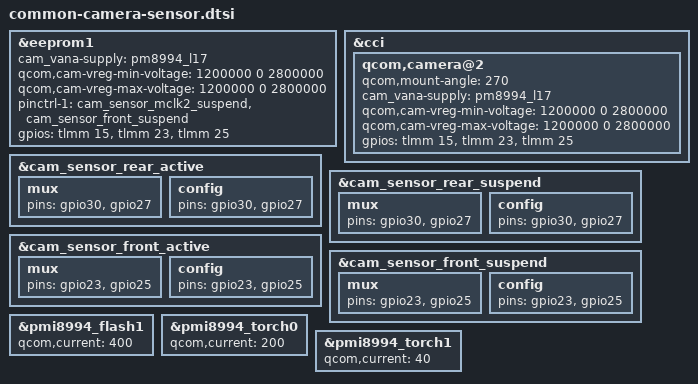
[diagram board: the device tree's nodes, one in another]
&eeprom1 {
	cam_vana-supply = <&pm8994_l17>;
	qcom,cam-vreg-min-voltage = <1200000 0 2800000>;
	qcom,cam-vreg-max-voltage = <1200000 0 2800000>;
	pinctrl-1 = <&cam_sensor_mclk2_suspend &cam_sensor_front_suspend>;
	gpios = <&tlmm 15 0>,
			<&tlmm 23 0>,
			<&tlmm 25 0>;
	/delete-property/ qcom,clock-rates;
};

&cci {
	/delete-node/ qcom,camera@1;
	
	qcom,camera@2 {
		qcom,mount-angle = <270>;
		/delete-property/ qcom,actuator-src;
		cam_vana-supply = <&pm8994_l17>;
		qcom,cam-vreg-min-voltage = <1200000 0 2800000>;
		qcom,cam-vreg-max-voltage = <1200000 0 2800000>;
		gpios = <&tlmm 15 0>,
			<&tlmm 23 0>,
			<&tlmm 25 0>;
		/delete-property/ qcom,clock-rates;
	};
};

&cam_sensor_rear_active {
	mux {
		pins = "gpio30", "gpio27";
	};
	config {
		pins = "gpio30", "gpio27";
	};
};

&cam_sensor_rear_suspend {
	mux {
		pins = "gpio30", "gpio27";
	};
	config {
		pins = "gpio30", "gpio27";
	};
};

&cam_sensor_front_active {
	mux {
		pins = "gpio23","gpio25";
	};
	config {
		pins = "gpio23","gpio25";
	};
};

&cam_sensor_front_suspend {
	mux {
		pins = "gpio23","gpio25";
	};
	config {
		pins = "gpio23","gpio25";
	};
};

&pmi8994_flash1 {
	qcom,current = <400>;
};

&pmi8994_torch0 {
	qcom,current = <200>;
};

&pmi8994_torch1 {
	qcom,current = <40>;
};
